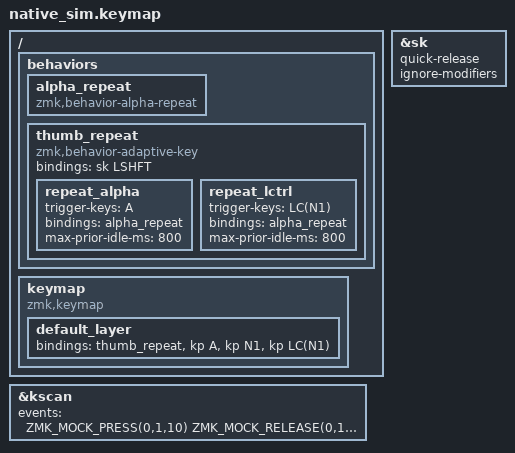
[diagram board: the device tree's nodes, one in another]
#include <behaviors.dtsi>
#include <dt-bindings/zmk/keys.h>
#include <dt-bindings/zmk/kscan_mock.h>
#include <zmk-helpers/helper.h>

/ {
    behaviors {
        alpha_repeat: alpha_repeat {
            compatible = "zmk,behavior-alpha-repeat";
            #binding-cells = <0>;
        };
    };

    keymap {
        compatible = "zmk,keymap";

        default_layer {
            bindings = <&thumb_repeat &kp A &kp N1 &kp LC(N1)>;
        };
    };
};

ZMK_ADAPTIVE_KEY(thumb_repeat, bindings = <&sk LSHFT>; repeat_alpha { trigger-keys = <A>; bindings = <&alpha_repeat>; max-prior-idle-ms = <800>; }; repeat_lctrl { trigger-keys = <LC(N1)>; bindings = <&alpha_repeat>; max-prior-idle-ms = <800>; };)

&sk {
    quick-release;
    ignore-modifiers;
};

&kscan {
    events = <
        ZMK_MOCK_PRESS(0,1,10)
        ZMK_MOCK_RELEASE(0,1,10)
        ZMK_MOCK_PRESS(0,0,10)
        ZMK_MOCK_RELEASE(0,0,10)

        ZMK_MOCK_PRESS(1,0,10)
        ZMK_MOCK_RELEASE(1,0,10)
        ZMK_MOCK_PRESS(0,0,10)
        ZMK_MOCK_RELEASE(0,0,10)
        ZMK_MOCK_PRESS(0,1,10)
        ZMK_MOCK_RELEASE(0,1,10)

        ZMK_MOCK_PRESS(1,1,10)
        ZMK_MOCK_RELEASE(1,1,10)
        ZMK_MOCK_PRESS(0,0,10)
        ZMK_MOCK_RELEASE(0,0,10)
    >;
};
